# LargeDummyDevice register map
File version: 1.0
Registers are 32-bit, read-write, no defined reset value unless marked. A register's access mark holds for its fields unless they carry their own. Offsets are from the block's base; [hi:lo] are bit positions.

## PERIPHERAL_24
Base 0x40017000
0x04 REG_1 — Register 1
  [29] FIELD_9, [33:29] FIELD_23, [28] FIELD_24, [28] FIELD_26, [28:27] FIELD_7, [29:25] FIELD_5, [27:24] FIELD_18, [24] FIELD_19, [23:22] FIELD_10, [21] FIELD_21, [22:19] FIELD_15, [19] FIELD_17, [21:18] FIELD_11, [21:18] FIELD_14, [22:18] FIELD_20, [19:16] FIELD_16, [15] FIELD_3, [16:14] FIELD_1, [14:13] FIELD_12, [13:10] FIELD_2, [9] FIELD_4, [11:9] FIELD_22, [7] FIELD_13, [7:6] FIELD_6, [9:5] FIELD_25, [8:4] FIELD_8
0x08 REG_2 — Register 2
  [33:30] FIELD_2, [32:30] FIELD_6, [33:30] FIELD_12, [29:28] FIELD_9, [30:27] FIELD_20, [30:26] FIELD_13, [29:26] FIELD_19, [28:24] FIELD_7, [23:20] FIELD_17, [22:18] FIELD_11, [17] FIELD_21, [17:16] FIELD_18, [17:15] FIELD_8, [10] FIELD_1, [10:9] FIELD_16, [12:8] FIELD_3, [6] FIELD_14, [5] FIELD_5, [4:3] FIELD_10, [4:3] FIELD_15, [4:0] FIELD_4
0x0C REG_3 — Register 3
  [33:31] FIELD_5, [33:30] FIELD_11, [30] FIELD_21, [32:28] FIELD_19, [31:27] FIELD_1, [27:25] FIELD_27, [25:24] FIELD_28, [23:20] FIELD_15, [21:20] FIELD_20, [22:18] FIELD_6, [19:16] FIELD_23, [15] FIELD_3, [17:15] FIELD_13, [15] FIELD_29, [18:14] FIELD_22, [17:13] FIELD_2, [13] FIELD_10, [16:12] FIELD_8, [13:12] FIELD_12, [15:12] FIELD_25, [15:11] FIELD_9, [12:10] FIELD_4, [14:10] FIELD_30, [12:8] FIELD_14, [6] FIELD_24, [10:6] FIELD_26, [5] FIELD_16, [5] FIELD_18, [6:3] FIELD_17, [3:2] FIELD_7, [2:1] FIELD_31
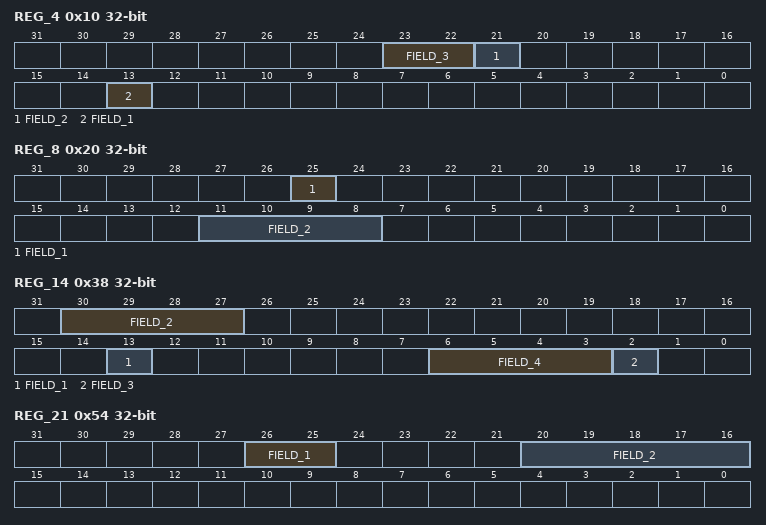
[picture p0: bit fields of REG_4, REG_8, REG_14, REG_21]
0x10 REG_4 — Register 4
  [23:22] FIELD_3, [21] FIELD_2, [13] FIELD_1
0x14 REG_5 — Register 5
  [31] FIELD_8, [31:30] FIELD_10, [29:27] FIELD_15, [26:24] FIELD_20, [24:22] FIELD_3, [21] FIELD_7, [19] FIELD_21, [21:18] FIELD_12, [19:16] FIELD_5, [18:16] FIELD_11, [18:15] FIELD_18, [16:14] FIELD_9, [15:13] FIELD_6, [16:13] FIELD_13, [16:12] FIELD_1, [16:12] FIELD_4, [11:7] FIELD_2, [7:6] FIELD_19, [8:5] FIELD_14, [7:4] FIELD_22, [4:3] FIELD_23, [0] FIELD_16, [0] FIELD_17
0x18 REG_6 — Register 6
  [35:31] FIELD_5, [29:27] FIELD_4, [28:27] FIELD_11, [28:24] FIELD_2, [24] FIELD_3, [26:22] FIELD_10, [19] FIELD_9, [23:19] FIELD_17, [19] FIELD_19, [17:13] FIELD_13, [14:11] FIELD_14, [10:9] FIELD_12, [8:7] FIELD_8, [10:7] FIELD_15, [9:5] FIELD_16, [6:4] FIELD_18, [6:3] FIELD_6, [2] FIELD_1, [3:0] FIELD_7, [1:0] FIELD_20
0x1C REG_7 — Register 7
  [29:26] FIELD_9, [25] FIELD_5, [23:22] FIELD_3, [21:20] FIELD_8, [13:10] FIELD_2, [12:9] FIELD_4, [13:9] FIELD_6, [6:5] FIELD_1, [6:4] FIELD_10, [6:3] FIELD_11, [3:1] FIELD_7
0x20 REG_8 — Register 8
  [25] FIELD_1, [11:8] FIELD_2
0x24 REG_9 — Register 9
  [32:31] FIELD_13, [34:30] FIELD_4, [31:29] FIELD_3, [26] FIELD_17, [29:26] FIELD_28, [25:24] FIELD_14, [27:23] FIELD_1, [25:23] FIELD_22, [27:23] FIELD_24, [26:23] FIELD_26, [25:23] FIELD_30, [24:22] FIELD_16, [21:20] FIELD_7, [23:19] FIELD_2, [18:17] FIELD_27, [19:16] FIELD_21, [19:15] FIELD_6, [13] FIELD_9, [14:12] FIELD_10, [13:12] FIELD_15, [13:12] FIELD_25, [11] FIELD_19, [8] FIELD_11, [7] FIELD_18, [11:7] FIELD_20, [9:6] FIELD_8, [4] FIELD_5, [4:2] FIELD_23, [1] FIELD_29, [1:0] FIELD_12
0x28 REG_10 — Register 10
  [33:30] FIELD_1, [30:28] FIELD_5, [31:28] FIELD_6, [23:22] FIELD_2, [18:17] FIELD_3, [19:16] FIELD_13, [20:16] FIELD_16, [17:14] FIELD_8, [17:14] FIELD_15, [14:12] FIELD_4, [9] FIELD_12, [9:6] FIELD_9, [5:4] FIELD_7, [6:2] FIELD_10, [4:2] FIELD_11, [1:0] FIELD_14
0x2C REG_11 — Register 11
  [35:31] FIELD_10, [29] FIELD_7, [29:28] FIELD_6, [29:25] FIELD_2, [24:23] FIELD_11, [20:18] FIELD_4, [20:18] FIELD_13, [19:17] FIELD_12, [18:16] FIELD_1, [14:11] FIELD_9, [9] FIELD_5, [9:7] FIELD_8, [4] FIELD_3
0x30 REG_12 — Register 12
  [32:30] FIELD_3, [32:28] FIELD_9, [30:27] FIELD_21, [30:26] FIELD_11, [28:25] FIELD_2, [28:25] FIELD_5, [27:24] FIELD_18, [26:24] FIELD_20, [25:23] FIELD_4, [25:21] FIELD_12, [24:21] FIELD_24, [20:18] FIELD_17, [20:18] FIELD_25, [18:17] FIELD_8, [14] FIELD_14, [15:12] FIELD_13, [13:11] FIELD_10, [13:11] FIELD_23, [12:10] FIELD_1, [10] FIELD_6, [9:7] FIELD_22, [8:5] FIELD_7, [5:4] FIELD_16, [5:3] FIELD_15, [6:3] FIELD_19
0x34 REG_13 — Register 13
  [32:29] FIELD_3, [31:29] FIELD_8, [32:29] FIELD_10, [32:29] FIELD_22, [29:28] FIELD_19, [27:26] FIELD_23, [24] FIELD_14, [27:24] FIELD_16, [25:23] FIELD_4, [23] FIELD_21, [23:22] FIELD_9, [24:22] FIELD_12, [23:21] FIELD_11, [21:20] FIELD_15, [20:19] FIELD_5, [22:19] FIELD_17, [17] FIELD_6, [16:12] FIELD_18, [14:12] FIELD_20, [5:4] FIELD_2, [8:4] FIELD_7, [6:3] FIELD_1, [3:1] FIELD_13
0x38 REG_14 — Register 14
  [30:27] FIELD_2, [13] FIELD_1, [6:3] FIELD_4, [2] FIELD_3
0x3C REG_15 — Register 15
  [30] FIELD_2, [33:29] FIELD_3, [28:27] FIELD_23, [28:26] FIELD_14, [27:26] FIELD_21, [29:26] FIELD_30, [27:25] FIELD_19, [25:22] FIELD_10, [26:22] FIELD_20, [20] FIELD_1, [21:20] FIELD_6, [24:20] FIELD_29, [19:18] FIELD_13, [21:17] FIELD_17, [18:17] FIELD_31, [20:16] FIELD_8, [15:13] FIELD_22, [12:11] FIELD_32, [12:10] FIELD_26, [12:9] FIELD_9, [12:9] FIELD_28, [9:7] FIELD_16, [9:7] FIELD_24, [9:6] FIELD_4, [9:6] FIELD_7, [10:6] FIELD_15, [10:6] FIELD_18, [6:4] FIELD_27, [3] FIELD_5, [2:0] FIELD_11, [4:0] FIELD_12, [3:0] FIELD_25
0x40 REG_16 — Register 16
  [34:31] FIELD_5, [25] FIELD_12, [28:24] FIELD_1, [26:24] FIELD_9, [21:19] FIELD_3, [21:18] FIELD_2, [18:17] FIELD_4, [16:13] FIELD_8, [13:11] FIELD_7, [4:3] FIELD_10, [1] FIELD_11, [3:0] FIELD_6
0x44 REG_17 — Register 17
  [30:27] FIELD_2, [24:23] FIELD_9, [23] FIELD_11, [24:21] FIELD_12, [17] FIELD_5, [17:16] FIELD_10, [17:15] FIELD_4, [16:13] FIELD_6, [15:12] FIELD_8, [6] FIELD_7, [2] FIELD_1, [4:0] FIELD_3
0x48 REG_18 — Register 18
  [30:27] FIELD_1
0x4C REG_19 — Register 19
  [34:30] FIELD_2, [25:23] FIELD_1, [11] FIELD_4, [6:5] FIELD_5, [2:1] FIELD_3
0x50 REG_20 — Register 20
  [35:31] FIELD_14, [33:31] FIELD_27, [31:29] FIELD_25, [32:28] FIELD_23, [28:24] FIELD_13, [28:24] FIELD_15, [25:24] FIELD_22, [24:23] FIELD_19, [26:23] FIELD_30, [24:22] FIELD_2, [26:22] FIELD_32, [21] FIELD_3, [25:21] FIELD_26, [19] FIELD_24, [22:19] FIELD_28, [22:19] FIELD_29, [22:18] FIELD_5, [21:18] FIELD_7, [19:18] FIELD_12, [19:18] FIELD_17, [20:18] FIELD_20, [20:17] FIELD_6, [18:17] FIELD_9, [19:17] FIELD_16, [19:16] FIELD_10, [19:15] FIELD_18, [14:13] FIELD_8, [11:10] FIELD_21, [8:6] FIELD_31, [9:5] FIELD_1, [8:4] FIELD_4, [7:4] FIELD_11
0x54 REG_21 — Register 21
  [26:25] FIELD_1, [20:16] FIELD_2
0x58 REG_22 — Register 22
  [30:26] FIELD_10, [29:26] FIELD_14, [28:25] FIELD_3, [25] FIELD_4, [26:25] FIELD_7, [24] FIELD_5, [24] FIELD_17, [23] FIELD_11, [22:18] FIELD_6, [19:18] FIELD_16, [11] FIELD_8, [15:11] FIELD_13, [11:8] FIELD_9, [9:7] FIELD_12, [9:7] FIELD_18, [7:5] FIELD_15, [6:3] FIELD_2, [1] FIELD_1
0x5C REG_23 — Register 23
  [30:26] FIELD_3, [19:16] FIELD_1, [20:16] FIELD_2
0x60 REG_24 — Register 24
  [33:29] FIELD_10, [29:26] FIELD_12, [28:24] FIELD_7, [21] FIELD_6, [19:18] FIELD_2, [21:18] FIELD_5, [17:15] FIELD_13, [16:14] FIELD_4, [13:11] FIELD_3, [12:10] FIELD_8, [6] FIELD_11, [8:4] FIELD_14, [4:3] FIELD_1, [7:3] FIELD_9
0x64 REG_25 — Register 25
  [32:29] FIELD_9, [32:29] FIELD_16, [33:29] FIELD_25, [32:28] FIELD_31, [29:26] FIELD_13, [30:26] FIELD_29, [27:25] FIELD_19, [26:23] FIELD_7, [23:21] FIELD_28, [22:19] FIELD_10, [20:17] FIELD_24, [20:16] FIELD_4, [20:16] FIELD_18, [18:15] FIELD_17, [14] FIELD_23, [15:14] FIELD_26, [17:13] FIELD_8, [14:11] FIELD_1, [12:11] FIELD_2, [14:11] FIELD_5, [11] FIELD_20, [14:10] FIELD_6, [11:10] FIELD_21, [10:9] FIELD_12, [8] FIELD_11, [7] FIELD_15, [8:7] FIELD_27, [4] FIELD_30, [1:0] FIELD_3, [1:0] FIELD_14, [1:0] FIELD_22
0x68 REG_26 — Register 26
  [28:24] FIELD_1, [16:15] FIELD_2, [8:4] FIELD_3, [4:1] FIELD_4
0x6C REG_27 — Register 27
  [29:26] FIELD_10, [28:26] FIELD_17, [25] FIELD_15, [21] FIELD_7, [20:18] FIELD_13, [20:17] FIELD_1, [13] FIELD_2, [16:12] FIELD_4, [12] FIELD_9, [11] FIELD_6, [12:8] FIELD_11, [9:6] FIELD_3, [9:6] FIELD_16, [7:5] FIELD_14, [7:4] FIELD_12, [4:1] FIELD_5, [0] FIELD_8
